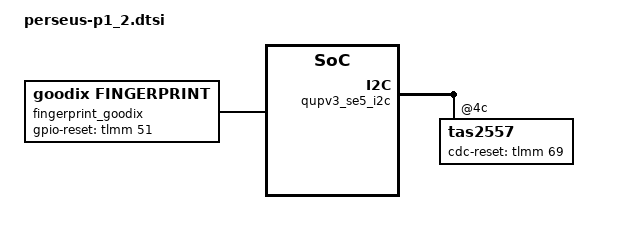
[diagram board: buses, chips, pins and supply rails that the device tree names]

/* Copyright (c) 2016-2017, The Linux Foundation. All rights reserved.
 * Copyright (C) 2018 XiaoMi, Inc.
 *
 * This program is free software; you can redistribute it and/or modify
 * it under the terms of the GNU General Public License version 2 and
 * only version 2 as published by the Free Software Foundation.
 *
 * This program is distributed in the hope that it will be useful,
 * but WITHOUT ANY WARRANTY; without even the implied warranty of
 * MERCHANTABILITY or FITNESS FOR A PARTICULAR PURPOSE.  See the
 * GNU General Public License for more details.
 */

#include "perseus-p1.dtsi"
#include "perseus-p1_2-camera-sensor-mtp.dtsi"

&qupv3_se5_i2c {
       status = "ok";
       tas2557@4c{
               ti,cdc-reset-gpio = <&tlmm 69 0>;
       };
};

&soc {
	fingerprint_fpc {
		status = "ok";
		compatible = "fpc,fpc1020";
		pinctrl-names = "fpc1020_reset_reset",
			"fpc1020_reset_active";

		pinctrl-0 = <&msm_gpio_51>;
		pinctrl-1 = <&msm_gpio_51_output_high>;
	};

	fingerprint_goodix {
		status = "ok";
		compatible = "goodix,fingerprint";
		gooidx,gpio-reset = <&tlmm 51 0x0>;
	};
};
